# AT32F403Axx register map
Vendor: Keil; Series: AT32F403A; File version: 1.0
CPU: CM4 r0p1, little endian, no MPU, FPU, 4 interrupt priority bits
Registers are 32-bit, read-write, reset 0x0 unless marked. A register's access mark holds for its fields unless they carry their own. Offsets are from the block's base; [hi:lo] are bit positions; {n}, {i} and the like mark numbered series; 'fields as' and 'values as' point back to an identical list.

## EXTI
Base 0x40010400
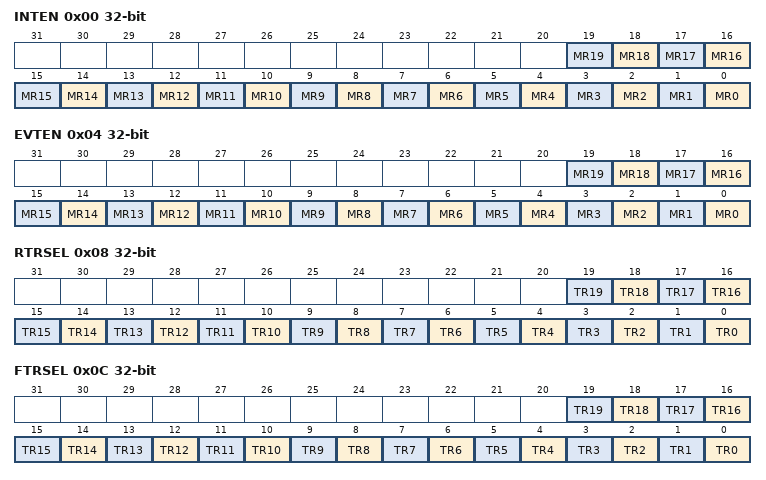
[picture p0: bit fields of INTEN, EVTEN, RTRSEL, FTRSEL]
0x00 INTEN — Interrupt mask register (EXTI_INTEN)
  [n] MR{n} (n=0..19) — Interrupt Mask on line {n}
0x04 EVTEN — Event mask register (EXTI_EVTEN)
  [n] MR{n} (n=0..19) — Event Mask on line {n}
0x08 RTRSEL — Rising Trigger selection register (EXTI_RTRSEL)
  [n] TR{n} (n=0..19) — Rising trigger event configuration of line {n}
0x0C FTRSEL — Falling Trigger selection register (EXTI_FTRSEL)
  [n] TR{n} (n=0..19) — Falling trigger event configuration of line {n}
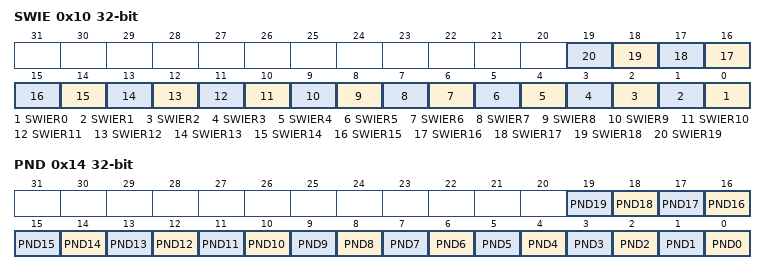
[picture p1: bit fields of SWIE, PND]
0x10 SWIE — Software interrupt event register (EXTI_SWIE)
  [n] SWIER{n} (n=0..19) — Software Interrupt on line {n}
0x14 PND — Pending register (EXTI_PND)
  [n] PND{n} (n=0..19) — Pending bit {n}

## DMA1 — DMA controller
Base 0x40020000
Same registers: DMA2 0x40020400
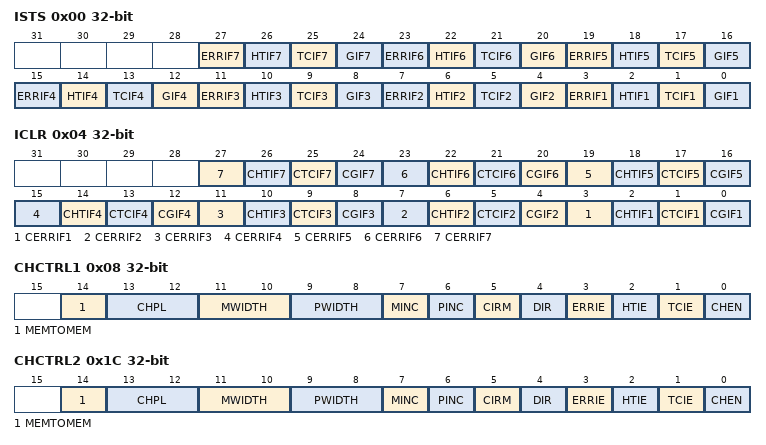
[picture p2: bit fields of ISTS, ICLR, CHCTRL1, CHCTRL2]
0x00 ISTS ro — DMA interrupt status register (DMA_ISTS)
  [4n-1] ERRIF{n} (n=1..7) — Channel {n} Transfer Error flag
  [4n-2] HTIF{n} (n=1..7) — Channel {n} Half Transfer Complete flag
  [4n-3] TCIF{n} (n=1..7) — Channel {n} Transfer Complete flag
  [4n-4] GIF{n} (n=1..7) — Channel {n} Global interrupt flag
0x04 ICLR — DMA interrupt flag clear register (DMA_ICLR)
  [4n-1] CERRIF{n} (n=1..7) — Channel {n} Transfer Error clear
  [4n-2] CHTIF{n} (n=1..7) — Channel {n} Half Transfer clear
  [4n-3] CTCIF{n} (n=1..7) — Channel {n} Transfer Complete clear
  [4n-4] CGIF{n} (n=1..7) — Channel {n} Global interrupt clear
0x08 CHCTRL1 — DMA channel configuration register (DMA_CCR)
  [14] MEMTOMEM — Memory to memory mode
  [13:12] CHPL — Channel Priority level
  [11:10] MWIDTH — Memory size
  [9:8] PWIDTH — Peripheral size
  [7] MINC — Memory increment mode
  [6] PINC — Peripheral increment mode
  [5] CIRM — Circular mode
  [4] DIR — Data transfer direction
  [3] ERRIE — Transfer error interrupt enable
  [2] HTIE — Half Transfer interrupt enable
  [1] TCIE — Transfer complete interrupt enable
  [0] CHEN — Channel enable
0x0C TCNT1 — DMA channel 1 number of data register
  [15:0] CNT — Number of data to transfer
0x10 CPBA1 — DMA channel 1 peripheral address register
  [31:0] PA — Peripheral address
{0x0+0x14*i} CMBA{i} (i=1..7) — DMA channel {i} memory address register
  [31:0] MA — Memory address
0x1C CHCTRL2 — DMA channel configuration register (DMA_CHCTRL2)
  fields as CHCTRL1
0x20 TCNT2 — DMA channel 2 number of data register
  [15:0] CNT — Number of data to transfer
0x24 CPBA2 — DMA channel 2 peripheral address register
  [31:0] PA — Peripheral address
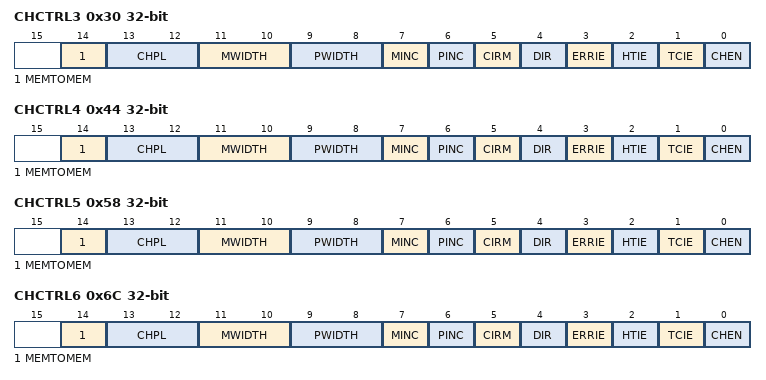
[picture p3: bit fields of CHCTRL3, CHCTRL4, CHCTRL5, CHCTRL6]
0x30 CHCTRL3 — DMA channel configuration register (DMA_CHCTRL3)
  fields as CHCTRL1
0x34 TCNT3 — DMA channel 3 number of data register
  [15:0] CNT — Number of data to transfer
0x38 CPBA3 — DMA channel 3 peripheral address register
  [31:0] PA — Peripheral address
0x44 CHCTRL4 — DMA channel configuration register (DMA_CHCTRL4)
  fields as CHCTRL1
0x48 TCNT4 — DMA channel 4 number of data register
  [15:0] CNT — Number of data to transfer
0x4C CPBA4 — DMA channel 4 peripheral address register
  [31:0] PA — Peripheral address
0x58 CHCTRL5 — DMA channel configuration register (DMA_CHCTRL5)
  fields as CHCTRL1
0x5C TCNT5 — DMA channel 5 number of data register
  [15:0] CNT — Number of data to transfer
0x60 CPBA5 — DMA channel 5 peripheral address register
  [31:0] PA — Peripheral address
0x6C CHCTRL6 — DMA channel configuration register (DMA_CHCTRL6)
  fields as CHCTRL1
0x70 TCNT6 — DMA channel 6 number of data register
  [15:0] CNT — Number of data to transfer
0x74 CPBA6 — DMA channel 6 peripheral address register
  [31:0] PA — Peripheral address
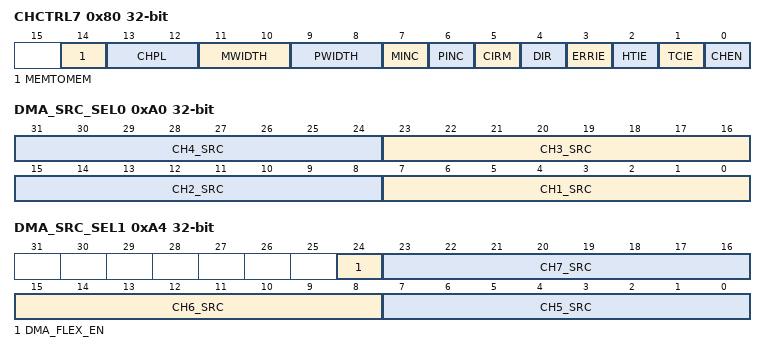
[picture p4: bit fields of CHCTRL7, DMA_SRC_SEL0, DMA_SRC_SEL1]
0x80 CHCTRL7 — DMA channel configuration register (DMA_CHCTRL7)
  fields as CHCTRL1
0x84 TCNT7 — DMA channel 7 number of data register
  [15:0] CNT — Number of data to transfer
0x88 CPBA7 — DMA channel 7 peripheral address register
  [31:0] PA — Peripheral address
0xA0 DMA_SRC_SEL0 — DMA channel source assignment register
  [8n-1:8n-8] CH{n}_SRC (n=1..4) — CH{n} SRC select
0xA4 DMA_SRC_SEL1 — DMA channel source assignment register
  [24] DMA_FLEX_EN — DMA FLEX Enable
  [23:16] CH7_SRC — CH7 SRC select
  [15:8] CH6_SRC — CH6 SRC select
  [7:0] CH5_SRC — CH5 SRC select
